# R7FA4E2B9 register map
Vendor: Renesas Electronics Corporation; Series: RA4; File version: 1.40.00
CPU: CM33 r0p4, little endian, MPU, FPU, VTOR, 4 interrupt priority bits, 96 interrupts
Registers are 32-bit, read-write, reset 0x0 unless marked. A register's access mark holds for its fields unless they carry their own. Offsets are from the block's base; [hi:lo] are bit positions; {n}, {i} and the like mark numbered series.

## CEC — Consumer Electronics Control
Base 0x400AC000
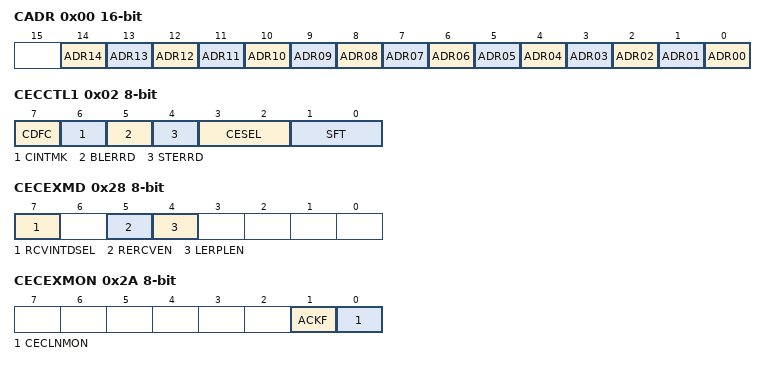
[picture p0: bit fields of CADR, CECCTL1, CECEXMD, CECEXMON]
0x00 CADR 16-bit — CEC Local Address Setting Register
  [all] fields
    0=Does not set as local address; 1=Sets as local address
  [14] ADR14 — Local Address Setting at Address 14 (specific use)
  [13] ADR13 — Local Address Setting at Address 13 (reserved)
  [12] ADR12 — Local Address Setting at Address 12 (reserved)
  [11] ADR11 — Local Address Setting at Address 11 (playback device 3)
  [10] ADR10 — Local Address Setting at Address 10 (tuner 4)
  [9] ADR09 — Local Address Setting at Address 9 (recording device 3)
  [8] ADR08 — Local Address Setting at Address 8 (playback device 2)
  [7] ADR07 — Local Address Setting at Address 7 (tuner 3)
  [6] ADR06 — Local Address Setting at Address 6 (tuner 2)
  [5] ADR05 — Local Address Setting at Address 5 (audio system)
  [4] ADR04 — Local Address Setting at Address 4 (playback device 1)
  [3] ADR03 — Local Address Setting at Address 3 (tuner 1)
  [2] ADR02 — Local Address Setting at Address 2 (recording device 2)
  [1] ADR01 — Local Address Setting at Address 1 (recording device 1)
  [0] ADR00 — Local Address at Address 0 (TV)
0x02 CECCTL1 8-bit — CEC Control Register 1
  [7] CDFC — Digital Filter Select
    0=Does not use a digital filter; 1=Uses a digital filter
  [6] CINTMK — CEC Data Interrupt (INTDA) Generation Select
    0=Does not generate an interrupt when the addresses do not match; 1=Generates an interrupt when the addresses do not match
  [5] BLERRD — Bus Lock Detection Select
    0=Does not detect sticking of receive data to high or low; 1=Detects sticking of receive data to high or low
  [4] STERRD — Start Bit Error Detection Select
    0=Does not detect timing errors during the start bit reception; 1=Detects timing errors during the start bit reception
  [3:2] CESEL — Communication Complete Interrupt (INTCE) Generation Timing Select
    0=Generates communication complete interrupt once after ACK transmission (reception) of the last frame (EOM = 1) is complete and another time after signal-free time is detected; 1=Generates communication complete interrupt after ACK transmission (reception) of the last frame (EOM = 1) is completed; 2=Generates communication complete interrupt after signal-free time is detected; 3=Setting prohibited
  [1:0] SFT — Signal-Free Time Data Bit Width Select
    0=3-data bit width; 1=5-data bit width; 2=7-data bit width; 3=Does not detect signal-free time
0x04 STATB 16-bit — CEC Transmission Start Bit Width Setting Register
  [8:0] STATB — CEC Transmission Start Bit Width Setting
0x06 STATL 16-bit — CEC Transmission Start Bit Low Width Setting Register
  [8:0] STATL — CEC Transmission Start Bit Low Width Setting
0x08 LGC0L 16-bit — CEC Transmission Logical 0 Low Width Setting Register
  [8:0] LGC0L — CEC Transmission Logical 0 Low Width Setting
0x0A LGC1L 16-bit — CEC Transmission Logical 1 Low Width Setting Register
  [8:0] LGC1L — CEC Transmission Logical 1 Low Width Setting
0x0C DATB 16-bit — CEC Transmission Data Bit Width Setting Register
  [8:0] DATB — CEC Transmission Data Bit Width Setting
0x0E NOMT 16-bit — CEC Reception Data Sampling Time Setting Register
  [8:0] NOMT — CEC Reception Data Sampling Time Setting,
0x10 STATLL 16-bit — CEC Reception Start Bit Minimum Low Width Setting Register
  [8:0] STATLL — CEC Reception Start Bit Minimum Low Width Setting
0x12 STATLH 16-bit — CEC Reception Start Bit Maximum Low Width Setting Register
  [8:0] STATLH — CEC Reception Start Bit Maximum Bit Width Setting
0x14 STATBL 16-bit — CEC Reception Start Bit Minimum Bit Width Setting Register
  [8:0] STATBL — CEC Reception Start Bit Minimum Bit Width Setting
0x16 STATBH 16-bit — CEC Reception Start Bit Maximum Bit Width Setting Register
  [8:0] STATBH — CEC Reception Start Bit Maximum Bit Width Setting
0x18 LGC0LL 16-bit — CEC Reception Logical 0 Minimum Low Width Setting Register
  [8:0] LGC0LL — CEC Reception Logical 0 Minimum Low Width Setting
0x1A LGC0LH 16-bit — CEC Reception Logical 0 Maximum Low Width Setting Register
  [8:0] LGC0LH — CEC Reception Logical 0 Minimum Low Width Setting
0x1C LGC1LL 16-bit — CEC Reception Logical 1 Minimum Low Width Setting Register
  [8:0] LGC1LL — CEC Reception Logical 1 Minimum Low Width Setting
0x1E LGC1LH 16-bit — CEC Reception Logical 1 Maximum Low Width Setting Register
  [8:0] LGC1LH — CEC Reception Logical 1 Maximum Low Width Setting
0x20 DATBL 16-bit — CEC Reception Data Bit Minimum Bit Width Setting Register
  [8:0] DATBL — CEC Reception Data Bit Minimum Bit Width Setting
0x22 DATBH 16-bit — CEC Reception Data Bit Maximum Bit Width Setting Register
  [8:0] DATBH — CEC Reception Data Bit Maximum Bit Width Setting
0x24 NOMP 16-bit — CEC Data Bit Reference Width Setting Register
  [8:0] NOMP — CEC Data Bit Reference Width Setting
0x28 CECEXMD 8-bit — CEC Extension Mode Register
  [7] RCVINTDSEL — INTDA Reception Interrupt Timing Change
    0=EOM timing (9th bit of data); 1=ACK timing (10th bit of data)
  [5] RERCVEN — Start Detection Reception Restart Enable
    0=Does not restart reception when the start bit is detected during reception; 1=Restarts reception when the start bit is detected during reception
  [4] LERPLEN — Pulse Output Function Enable by Long Bit Width Error
    0=Detects only a long bit width error; 1=Detects a long bit width error and outputs an error handling pulse
0x2A CECEXMON 8-bit (reset mask 0xFE) — CEC Extension Monitor Register
  [1] ACKF ro — ACK Flag
  [0] CECLNMON ro — CEC Line Monitor
    0=Low level; 1=High level
0x40 CTXD 8-bit — CEC Transmission Buffer Register
0x41 CRXD 8-bit — CEC Reception Buffer Register
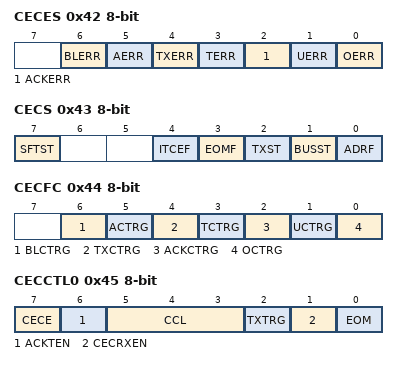
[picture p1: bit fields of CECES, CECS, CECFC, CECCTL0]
0x42 CECES 8-bit — CEC Communication Error Status Register
  [6] BLERR ro — Bus Lock Error Detection Flag
    0=No bus lock error has occurred; 1=A bus lock error has occurred
  [5] AERR ro — Arbitration Loss Detection Flag
    0=No arbitration loss has occurred; 1=An arbitration loss has occurred
  [4] TXERR ro — Transmission Error Detection Flag
    0=No transmission error has occurred; 1=A transmission error has occurred
  [3] TERR ro — Timing Error Detection Flag
    0=No timing error has occurred; 1=A timing error has occurred
  [2] ACKERR ro — ACK Error Detection Flag
    0=No ACK error has occurred; 1=An ACK error has occurred
  [1] UERR ro — Underrun Error Detection Flag
    0=No underrun error has occurred; 1=An underrun error has occurred
  [0] OERR ro — Overrun Error Detection Flag
    0=No overrun error has occurred; 1=An overrun error has occurred
0x43 CECS 8-bit — CEC Communication Status Register
  [7] SFTST ro — Signal-Free Time Rewrite Disable Report Flag
    0=Enables rewriting CECCTL1.SFT[1:0]; 1=Disables rewriting CECCTL1.SFT[1:0]
  [4] ITCEF ro — INTCE Generation Source Flag
    0=Generates a communication complete interrupt (INTCE) if the signal-free time is counted; 1=Generates INTCE if communication is complete or an error is detected
  [3] EOMF ro — EOM Flag
    0=The EOM flag received immediately before is logically 0; 1=The EOM flag received immediately before is logically 1
  [2] TXST ro — Transmission Status Flag
    0=During communication standby state or reception (a follower is operating.); 1=During transmission (an initiator is operating.)
  [1] BUSST ro — Bus Busy Detection Flag
    0=Bus-free state; 1=Bus-busy state
  [0] ADRF ro — Address Match Detection Flag
    0=During communication between other stations, while communication is stopped, or while the local station is transmitting; 1=During local reception
0x44 CECFC 8-bit — CEC Communication Error Flag Clear Trigger Register
  [6] BLCTRG wo — Bus Lock Error Detection Flag Clear Trigger
    0=Does not clear bus lock error detection flag; 1=Clears bus lock error detection flag
  [5] ACTRG wo — Arbitration Loss Detection Flag Clear Trigger
    0=Does not clear arbitration loss detection flag; 1=Clears arbitration loss detection flag
  [4] TXCTRG wo — Transmission Error Detection Flag Clear Trigger
    0=Does not clear transmission error detection flag; 1=Clears transmission error detection flag
  [3] TCTRG wo — Timing Error Detection Flag Clear Trigger
    0=Does not clear timing error detection flag; 1=Clears timing error detection flag
  [2] ACKCTRG wo — ACK Error Detection Flag Clear Trigger
    0=Does not clear ACK error detection flag; 1=Clears ACK error detection flag
  [1] UCTRG wo — Underrun Error Detection Flag Clear Trigger
    0=Does not clear underrun error detection flag; 1=Clears underrun error detection flag
  [0] OCTRG wo — Overrun Error Detection Flag Clear Trigger
    0=Does not clear overrun error detection flag; 1=Clears overrun error detection flag
0x45 CECCTL0 8-bit — CEC Control Register 0
  [7] CECE — CEC Operation Enable Flag
    0=Disables CEC operation; 1=Enables CEC operation
  [6] ACKTEN — ACK Bit Timing Error (Bit Width) Check Enable
    0=Does not detect ACK bit timing errors; 1=Detects ACK bit timing errors
  [5:3] CCL — CEC Clock Select
    {v}=PCLKB/{v+25} (v=0..4); 5=PCLKB/210; 6=CECCLK (when using SOSC); 7=CECCLK/28 (when using MOSC)
  [2] TXTRG wo — Transmission Start Trigger
    0=No effect; 1=Starts CEC transmission
  [1] CECRXEN — Reception Enable Control
    0=Disables continuing reception or reports abnormal reception; 1=Enables continuing reception or reports normal reception. lists the reception status and ACK/NACK timing output.
  [0] EOM — EOM Setting
    0=Continues transmission; 1=Last frame

## Notices in the file
This software is supplied by Renesas Electronics Corporation and is only intended for
use with Renesas products. No other uses are authorized. This software is owned by
Renesas Electronics Corporation and is protected under all applicable laws, including
copyright laws.
THIS SOFTWARE IS PROVIDED "AS IS" AND RENESAS MAKES NO WARRANTIES REGARDING
THIS SOFTWARE, WHETHER EXPRESS, IMPLIED OR STATUTORY, INCLUDING BUT NOT LIMITED TO
WARRANTIES OF MERCHANTABILITY, FITNESS FOR A PARTICULAR PURPOSE AND NON-INFRINGEMENT.
ALL SUCH WARRANTIES ARE EXPRESSLY DISCLAIMED. TO THE MAXIMUM EXTENT PERMITTED NOT
PROHIBITED BY LAW, NEITHER RENESAS ELECTRONICS CORPORATION NOR ANY OF ITS AFFILIATED
COMPANIES SHALL BE LIABLE FOR ANY DIRECT, INDIRECT, SPECIAL, INCIDENTAL OR CONSEQUENTIAL
DAMAGES FOR ANY REASON RELATED TO THIS SOFTWARE, EVEN IF RENESAS OR ITS AFFILIATES HAVE
BEEN ADVISED OF THE POSSIBILITY OF SUCH DAMAGES.
Renesas reserves the right, without notice, to make changes to this software and to
discontinue the availability of this software. By using this software, you agree to
the additional terms and conditions found by accessing the following link:
http://www.renesas.com/disclaimer
